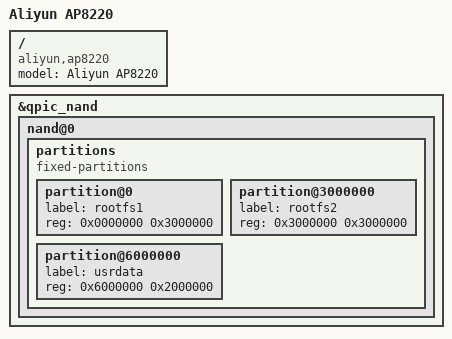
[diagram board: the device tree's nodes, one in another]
// SPDX-License-Identifier: GPL-2.0-or-later OR MIT

/dts-v1/;

#include "ipq8071-ap8220.dtsi"

/ {
	model = "Aliyun AP8220";
	compatible = "aliyun,ap8220", "qcom,ipq8074";
};

&qpic_nand {
	nand@0 {
		partitions {
			compatible = "fixed-partitions";
			#address-cells = <1>;
			#size-cells = <1>;

			partition@0 {
				label = "rootfs1";
				reg = <0x0000000 0x3000000>;
			};

			partition@3000000 {
				label = "rootfs2";
				reg = <0x3000000 0x3000000>;
			};

			partition@6000000 {
				label = "usrdata";
				reg = <0x6000000 0x2000000>;
			};
		};
	};
};
